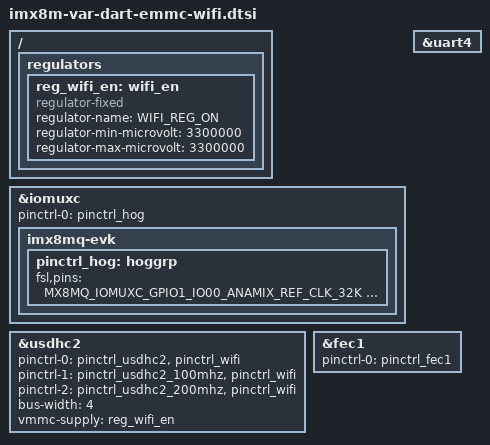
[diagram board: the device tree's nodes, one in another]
/*
 * Copyright 2017 NXP
 * Copyright 2018 Variscite Ltd.
 *
 * This program is free software; you can redistribute it and/or
 * modify it under the terms of the GNU General Public License
 * as published by the Free Software Foundation; either version 2
 * of the License, or (at your option) any later version.
 *
 * This program is distributed in the hope that it will be useful,
 * but WITHOUT ANY WARRANTY; without even the implied warranty of
 * MERCHANTABILITY or FITNESS FOR A PARTICULAR PURPOSE.  See the
 * GNU General Public License for more details.
 */

/ {
	regulators {
		reg_wifi_en: wifi_en {
			compatible = "regulator-fixed";
			regulator-name = "WIFI_REG_ON";
			regulator-min-microvolt = <3300000>;
			regulator-max-microvolt = <3300000>;
		};
	};
};

&iomuxc {
	pinctrl-names = "default";
	pinctrl-0 = <&pinctrl_hog>;

	/* Start WIFI slow clock before WIFI power is switched on */ 
	imx8mq-evk {
		pinctrl_hog: hoggrp {
			fsl,pins = <
				MX8MQ_IOMUXC_GPIO1_IO00_ANAMIX_REF_CLK_32K	0xc1    /* WIFI slow clock  */
			>;
		};
	};
};

/* Bluetooth */
&uart4 {
	status = "okay";
};

/* WIFI */
&usdhc2 {
	pinctrl-names = "default", "state_100mhz", "state_200mhz";
	pinctrl-0 = <&pinctrl_usdhc2>, <&pinctrl_wifi>;
	pinctrl-1 = <&pinctrl_usdhc2_100mhz>, <&pinctrl_wifi>;
	pinctrl-2 = <&pinctrl_usdhc2_200mhz>, <&pinctrl_wifi>;
	bus-width = <4>;
	vmmc-supply = <&reg_wifi_en>;
	status = "okay";
};

&fec1 {
	pinctrl-names = "default";
	pinctrl-0 = <&pinctrl_fec1>;
};

